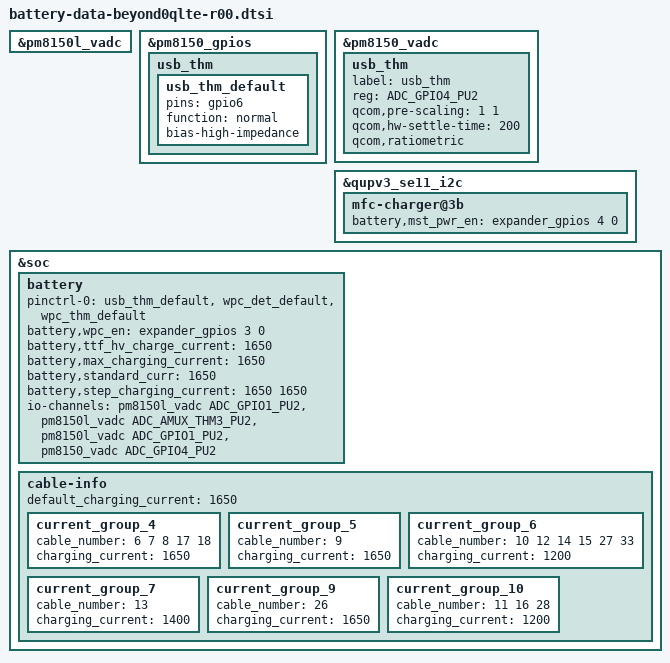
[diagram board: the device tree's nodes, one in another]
/*
 * SAMSUNG board device tree source
 *
 * Copyright (c) 2018 Samsung Electronics Co., Ltd.
 *		http://www.samsung.com
 *
 * This program is free software; you can redistribute it and/or modify
 * it under the terms of the GNU General Public License version 2 as
 * published by the Free Software Foundation.
 */

/* This dtsi is for hw rev from 00 to 03 */
#include "battery-data-beyond0qlte-common.dtsi"

&pm8150l_vadc {
	/delete-node/ usb_thm;
};

&pm8150_gpios {
	usb_thm { /* GPIO_06 */
		usb_thm_default: usb_thm_default {
			pins = "gpio6";
			function = "normal";
			bias-high-impedance;
		};
	};
};

&pm8150_vadc {
	usb_thm { /* GPIO_06 */
		label = "usb_thm";
		reg = <ADC_GPIO4_PU2>;
		qcom,pre-scaling = <1 1>;
		qcom,hw-settle-time = <200>;
		qcom,ratiometric;
	};
};

&qupv3_se11_i2c {
	mfc-charger@3b {
		battery,mst_pwr_en = <&expander_gpios 4 0>; /* MST_PWR_EN */
	};
};

&soc {
	battery {
		pinctrl-0 = <&usb_thm_default &wpc_det_default &wpc_thm_default>;
		battery,wpc_en = <&expander_gpios 3 0>; /* WPC_EN */

		battery,ttf_hv_charge_current = <1650>;
		battery,max_charging_current = <1650>;
		battery,standard_curr = <1650>;
		
		battery,step_charging_current = <1650 1650>;

		io-channels = <&pm8150l_vadc ADC_GPIO1_PU2>, <&pm8150l_vadc ADC_AMUX_THM3_PU2>, <&pm8150l_vadc ADC_GPIO1_PU2>, <&pm8150_vadc ADC_GPIO4_PU2>;
	};

	cable-info {
		default_charging_current = <1650>;

		current_group_4 {
			cable_number = <6 7 8 17 18>;
			charging_current = <1650>;
		};
		current_group_5 {
			cable_number = <9>;
			charging_current = <1650>;
		};
		current_group_6 {
			cable_number = <10 12 14 15 27 33>;
			charging_current = <1200>;
		};
		current_group_7 {
			cable_number = <13>;
			charging_current = <1400>;
		};
		current_group_9 {
			cable_number = <26>;
			charging_current = <1650>;
		};
		current_group_10 {
			cable_number = <11 16 28>;
			charging_current = <1200>;
		};
	};
};
